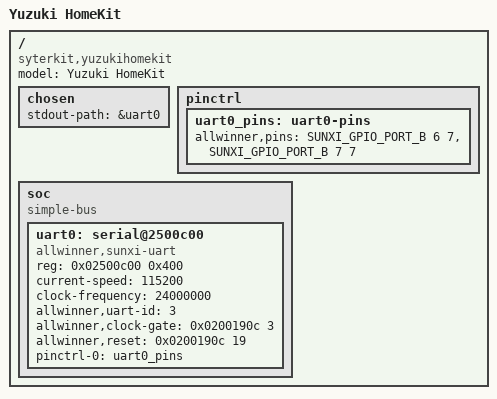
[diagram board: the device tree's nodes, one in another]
// SPDX-License-Identifier: GPL-2.0+
/dts-v1/;

#include <dt-bindings/gpio/sunxi-gpio.h>

/ {
	#address-cells = <1>;
	#size-cells = <1>;
	model = "Yuzuki HomeKit";
	compatible = "syterkit,yuzukihomekit";

	chosen {
		stdout-path = &uart0;
	};

	pinctrl {
		uart0_pins: uart0-pins {
			allwinner,pins =
				<SUNXI_GPIO_PORT_B 6 7>,
				<SUNXI_GPIO_PORT_B 7 7>;
		};
	};

	soc {
		compatible = "simple-bus";
		#address-cells = <1>;
		#size-cells = <1>;
		ranges;

		uart0: serial@2500c00 {
			compatible = "allwinner,sunxi-uart";
			reg = <0x02500c00 0x400>;
			current-speed = <115200>;
			clock-frequency = <24000000>;
			allwinner,uart-id = <3>;
			allwinner,clock-gate = <0x0200190c 3>;
			allwinner,reset = <0x0200190c 19>;
			pinctrl-names = "default";
			pinctrl-0 = <&uart0_pins>;
			status = "okay";
		};
	};
};
